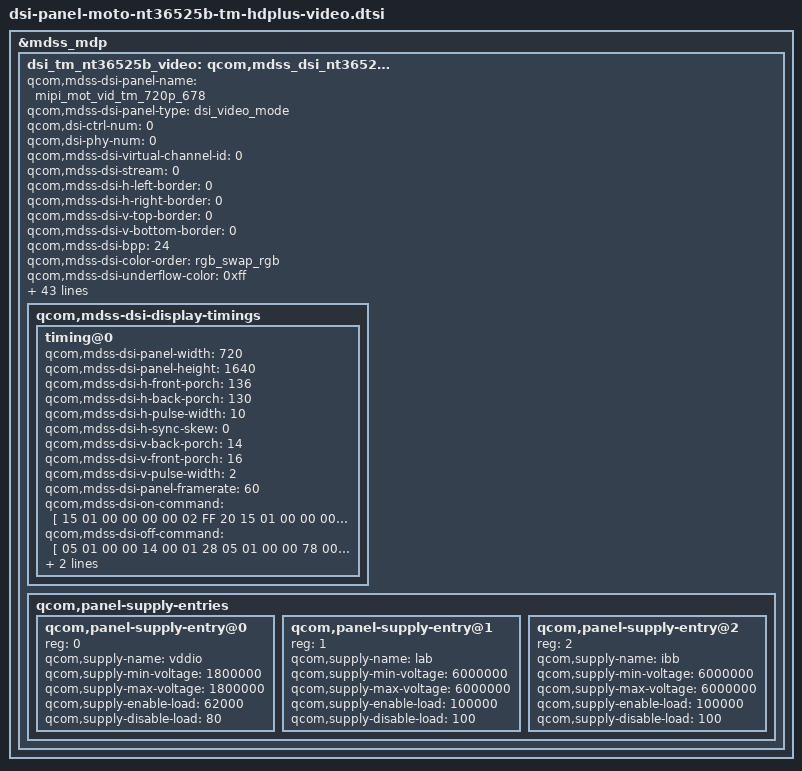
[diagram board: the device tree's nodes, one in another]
/* Copyright (c) 2015, 2018, The Linux Foundation. All rights reserved.
 *
 * This program is free software; you can redistribute it and/or modify
 * it under the terms of the GNU General Public License version 2 and
 * only version 2 as published by the Free Software Foundation.
 *
 * This program is distributed in the hope that it will be useful,
 * but WITHOUT ANY WARRANTY; without even the implied warranty of
 * MERCHANTABILITY or FITNESS FOR A PARTICULAR PURPOSE.  See the
 * GNU General Public License for more details.
 */

/*---------------------------------------------------------------------------
 * This file is autogenerated file using gcdb parser. Please do not edit it.
 * Update input XML file to add a new entry or update variable in this file
 * VERSION = "1.0"
 *---------------------------------------------------------------------------
 */

&mdss_mdp {
	dsi_tm_nt36525b_video:qcom,mdss_dsi_nt36525b_tm_video {
		qcom,mdss-dsi-panel-name ="mipi_mot_vid_tm_720p_678";
		qcom,mdss-dsi-panel-type = "dsi_video_mode";

		qcom,dsi-ctrl-num = <0>;
		qcom,dsi-phy-num = <0>;

		qcom,mdss-dsi-virtual-channel-id = <0>;
		qcom,mdss-dsi-stream = <0>;
		qcom,mdss-dsi-h-left-border = <0>;
		qcom,mdss-dsi-h-right-border = <0>;
		qcom,mdss-dsi-v-top-border = <0>;
		qcom,mdss-dsi-v-bottom-border = <0>;
		qcom,mdss-dsi-bpp = <24>;
		qcom,mdss-dsi-color-order = "rgb_swap_rgb";
		qcom,mdss-dsi-underflow-color = <0xff>;
		qcom,mdss-dsi-border-color = <0>;
		qcom,mdss-dsi-h-sync-pulse = <0>;
		qcom,mdss-dsi-traffic-mode = "non_burst_sync_event";
		qcom,mdss-dsi-lane-map = "lane_map_0123";
		qcom,mdss-dsi-bllp-eof-power-mode;
		qcom,mdss-dsi-bllp-power-mode;
		qcom,mdss-dsi-tx-eot-append;
		qcom,mdss-dsi-lane-0-state;
		qcom,mdss-dsi-lane-1-state;
		qcom,mdss-dsi-lane-2-state;
		qcom,mdss-dsi-lane-3-state;
		qcom,mdss-dsi-dma-trigger = "trigger_sw";
		qcom,mdss-dsi-mdp-trigger = "none";
		qcom,mdss-dsi-lp11-init;
		//qcom,mdss-dsi-reset-always-high;
		//qcom,mdss-panel-on-tp-rst-enable;
		qcom,mdss-dsi-reset-sequence = <1 10>, <0 10>, <1 10>;
		qcom,mdss-pan-physical-width-dimension = <69>;
		qcom,mdss-pan-physical-height-dimension = <158>;

		qcom,mdss-dsi-bl-pmic-control-type = "bl_ctrl_wled";
		qcom,mdss-dsi-bl-min-level = <1>;
		qcom,mdss-dsi-bl-max-level = <2047>;
		qcom,mdss-dsi-bl-default-level = <127>;

		qcom,mdss-dsi-cabc-ui-command = [15 01 00 00 00 00 02 55 00];
		qcom,mdss-dsi-cabc-ui-command-state = "dsi_hs_mode";
		qcom,mdss-dsi-cabc-mv-command = [15 01 00 00 00 00 02 55 00];
		qcom,mdss-dsi-cabc-mv-command-state = "dsi_hs_mode";
		qcom,mdss-dsi-cabc-dis-command = [15 01 00 00 00 00 02 55 00];
		qcom,mdss-dsi-cabc-dis-command-state = "dsi_hs_mode";
		qcom,mdss-dsi-hbm-on-command = [39 01 00 00 00 00 03 51 07 FF];
		qcom,mdss-dsi-hbm-on-command-state = "dsi_hs_mode";
		qcom,mdss-dsi-hbm-off-command = [39 01 00 00 00 00 03 51 06 66];
		qcom,mdss-dsi-hbm-off-command-state = "dsi_hs_mode";

		qcom,mdss-dsi-display-timings {
			timing@0{
				qcom,mdss-dsi-panel-width = <720>;
				qcom,mdss-dsi-panel-height = <1640>;
				qcom,mdss-dsi-h-front-porch = <136>;
				qcom,mdss-dsi-h-back-porch = <130>;
				qcom,mdss-dsi-h-pulse-width = <10>;
				qcom,mdss-dsi-h-sync-skew = <0>;
				qcom,mdss-dsi-v-back-porch = <14>;
				qcom,mdss-dsi-v-front-porch = <16>;
				qcom,mdss-dsi-v-pulse-width = <2>;
				qcom,mdss-dsi-panel-framerate = <60>;
				qcom,mdss-dsi-on-command = [
					15 01 00 00 00 00 02 FF 20
					15 01 00 00 00 00 02 FB 01
					15 01 00 00 00 00 02 05 A9
					15 01 00 00 00 00 02 07 6E
					15 01 00 00 00 00 02 08 AD
					15 01 00 00 00 00 02 0E 87
					15 01 00 00 00 00 02 0F 46
					15 01 00 00 00 00 02 69 A9
					15 01 00 00 00 00 02 87 02
					15 01 00 00 00 00 02 89 C1
					15 01 00 00 00 00 02 8A A8
					15 01 00 00 00 00 02 8B B1
					15 01 00 00 00 00 02 8C A8
					15 01 00 00 00 00 02 94 40
					15 01 00 00 00 00 02 95 D7
					15 01 00 00 00 00 02 96 13
					15 01 00 00 00 00 02 23 01
					15 01 00 00 00 00 02 24 01
					15 01 00 00 00 00 02 25 25
					15 01 00 00 00 00 02 26 92
					15 01 00 00 00 00 02 FF 24
					15 01 00 00 00 00 02 FB 01
					15 01 00 00 00 00 02 00 00
					15 01 00 00 00 00 02 01 1E
					15 01 00 00 00 00 02 02 23
					15 01 00 00 00 00 02 03 08
					15 01 00 00 00 00 02 04 08
					15 01 00 00 00 00 02 05 20
					15 01 00 00 00 00 02 06 20
					15 01 00 00 00 00 02 07 04
					15 01 00 00 00 00 02 08 05
					15 01 00 00 00 00 02 09 0F
					15 01 00 00 00 00 02 0A 0E
					15 01 00 00 00 00 02 0B 0D
					15 01 00 00 00 00 02 0C 0C
					15 01 00 00 00 00 02 16 20
					15 01 00 00 00 00 02 17 1E
					15 01 00 00 00 00 02 18 23
					15 01 00 00 00 00 02 19 08
					15 01 00 00 00 00 02 1A 08
					15 01 00 00 00 00 02 1B 20
					15 01 00 00 00 00 02 1C 20
					15 01 00 00 00 00 02 1D 04
					15 01 00 00 00 00 02 1E 05
					15 01 00 00 00 00 02 1F 0F
					15 01 00 00 00 00 02 20 0E
					15 01 00 00 00 00 02 21 0D
					15 01 00 00 00 00 02 22 0C
					15 01 00 00 00 00 02 37 44
					15 01 00 00 00 00 02 2F 06
					15 01 00 00 00 00 02 30 04
					15 01 00 00 00 00 02 33 04
					15 01 00 00 00 00 02 34 06
					15 01 00 00 00 00 02 39 00
					15 01 00 00 00 00 02 3A 05
					15 01 00 00 00 00 02 3B A0
					15 01 00 00 00 00 02 3D 52
					15 01 00 00 00 00 02 3F 0A
					15 01 00 00 00 00 02 43 0A
					15 01 00 00 00 00 02 47 44
					15 01 00 00 00 00 02 4A 05
					15 01 00 00 00 00 02 4B A0
					15 01 00 00 00 00 02 4C 51
					15 01 00 00 00 00 02 4D 12
					15 01 00 00 00 00 02 4E 34
					15 01 00 00 00 00 02 51 43
					15 01 00 00 00 00 02 52 21
					15 01 00 00 00 00 02 55 44
					15 01 00 00 00 00 02 56 54
					15 01 00 00 00 00 02 58 21
					15 01 00 00 00 00 02 59 00
					15 01 00 00 00 00 02 5A 84
					15 01 00 00 00 00 02 5B 70
					15 01 00 00 00 00 02 5C 80
					15 01 00 00 00 00 02 5D 05
					15 01 00 00 00 00 02 5E 04
					15 01 00 00 00 00 02 60 80
					15 01 00 00 00 00 02 61 9A
					15 01 00 00 00 00 02 64 10
					15 01 00 00 00 00 02 85 02
					15 01 00 00 00 00 02 92 A1
					15 01 00 00 00 00 02 93 10
					15 01 00 00 00 00 02 94 10
					15 01 00 00 00 00 02 9D 30
					15 01 00 00 00 00 02 AB 00
					15 01 00 00 00 00 02 AC 00
					15 01 00 00 00 00 02 AD 00
					15 01 00 00 00 00 02 B0 05
					15 01 00 00 00 00 02 B1 9D
					15 01 00 00 00 00 02 FF 25
					15 01 00 00 00 00 02 FB 01
					15 01 00 00 00 00 02 0A 82
					15 01 00 00 00 00 02 0B 65
					15 01 00 00 00 00 02 0C 01
					15 01 00 00 00 00 02 17 82
					15 01 00 00 00 00 02 18 06
					15 01 00 00 00 00 02 19 0F
					15 01 00 00 00 00 02 1E 00
					15 01 00 00 00 00 02 1F 80
					15 01 00 00 00 00 02 20 7C
					15 01 00 00 00 00 02 23 05
					15 01 00 00 00 00 02 24 9D
					15 01 00 00 00 00 02 25 00
					15 01 00 00 00 00 02 26 80
					15 01 00 00 00 00 02 27 7C
					15 01 00 00 00 00 02 2A 05
					15 01 00 00 00 00 02 2B 9D
					15 01 00 00 00 00 02 2F 66
					15 01 00 00 00 00 02 30 00
					15 01 00 00 00 00 02 31 00
					15 01 00 00 00 00 02 32 00
					15 01 00 00 00 00 02 33 80
					15 01 00 00 00 00 02 34 7C
					15 01 00 00 00 00 02 37 05
					15 01 00 00 00 00 02 38 9D
					15 01 00 00 00 00 02 40 11
					15 01 00 00 00 00 02 41 80
					15 01 00 00 00 00 02 42 80
					15 01 00 00 00 00 02 43 7C
					15 01 00 00 00 00 02 46 05
					15 01 00 00 00 00 02 47 9D
					15 01 00 00 00 00 02 4A 00
					15 01 00 00 00 00 02 4B 05
					15 01 00 00 00 00 02 4C A0
					15 01 00 00 00 00 02 4F 80
					15 01 00 00 00 00 02 50 7C
					15 01 00 00 00 00 02 53 05
					15 01 00 00 00 00 02 54 9D
					15 01 00 00 00 00 02 55 05
					15 01 00 00 00 00 02 56 9D
					15 01 00 00 00 00 02 58 00
					15 01 00 00 00 00 02 59 00
					15 01 00 00 00 00 02 5A 22
					15 01 00 00 00 00 02 5B C0
					15 01 00 00 00 00 02 5C 00
					15 01 00 00 00 00 02 5D 05
					15 01 00 00 00 00 02 5E A0
					15 01 00 00 00 00 02 61 80
					15 01 00 00 00 00 02 62 7C
					15 01 00 00 00 00 02 65 05
					15 01 00 00 00 00 02 66 9D
					15 01 00 00 00 00 02 6B 44
					15 01 00 00 00 00 02 6C 0D
					15 01 00 00 00 00 02 6D 0D
					15 01 00 00 00 00 02 6E 0F
					15 01 00 00 00 00 02 6F 0F
					15 01 00 00 00 00 02 78 00
					15 01 00 00 00 00 02 79 60
					15 01 00 00 00 00 02 7A 00
					15 01 00 00 00 00 02 7B 01
					15 01 00 00 00 00 02 8A 02
					15 01 00 00 00 00 02 CA 1C
					15 01 00 00 00 00 02 CC 1C
					15 01 00 00 00 00 02 CD 00
					15 01 00 00 00 00 02 CE 00
					15 01 00 00 00 00 02 CF 1C
					15 01 00 00 00 00 02 D0 00
					15 01 00 00 00 00 02 D1 00
					15 01 00 00 00 00 02 D3 11
					15 01 00 00 00 00 02 D4 CC
					15 01 00 00 00 00 02 D5 11
					15 01 00 00 00 00 02 FF 26
					15 01 00 00 00 00 02 FB 01
					15 01 00 00 00 00 02 00 A1
					15 01 00 00 00 00 02 04 4A
					15 01 00 00 00 00 02 0C 0B
					15 01 00 00 00 00 02 0D 01
					15 01 00 00 00 00 02 0E 02
					15 01 00 00 00 00 02 0F 06
					15 01 00 00 00 00 02 10 07
					15 01 00 00 00 00 02 11 00
					15 01 00 00 00 00 02 13 28
					15 01 00 00 00 00 02 14 94
					15 01 00 00 00 00 02 16 81
					15 01 00 00 00 00 02 19 1A
					15 01 00 00 00 00 02 1A 00
					15 01 00 00 00 00 02 1B 12
					15 01 00 00 00 00 02 1C 82
					15 01 00 00 00 00 02 1D 00
					15 01 00 00 00 00 02 1E A1
					15 01 00 00 00 00 02 1F A1
					15 01 00 00 00 00 02 24 01
					15 01 00 00 00 00 02 25 A1
					15 01 00 00 00 00 02 2F 03
					15 01 00 00 00 00 02 30 A2
					15 01 00 00 00 00 02 31 11
					15 01 00 00 00 00 02 32 11
					15 01 00 00 00 00 02 34 03
					15 01 00 00 00 00 02 35 A2
					15 01 00 00 00 00 02 36 78
					15 01 00 00 00 00 02 37 16
					15 01 00 00 00 00 02 38 11
					15 01 00 00 00 00 02 3F 04
					15 01 00 00 00 00 02 40 A1
					15 01 00 00 00 00 02 41 00
					15 01 00 00 00 00 02 42 00
					15 01 00 00 00 00 02 49 00
					15 01 00 00 00 00 02 58 C5
					15 01 00 00 00 00 02 59 C5
					15 01 00 00 00 00 02 5A C5
					15 01 00 00 00 00 02 5B BE
					15 01 00 00 00 00 02 5C 01
					15 01 00 00 00 00 02 5D 06
					15 01 00 00 00 00 02 5E 04
					15 01 00 00 00 00 02 5F 00
					15 01 00 00 00 00 02 60 00
					15 01 00 00 00 00 02 61 00
					15 01 00 00 00 00 02 62 00
					15 01 00 00 00 00 02 63 60
					15 01 00 00 00 00 02 64 B0
					15 01 00 00 00 00 02 65 05
					15 01 00 00 00 00 02 66 50
					15 01 00 00 00 00 02 67 94
					15 01 00 00 00 00 02 68 7C
					15 01 00 00 00 00 02 6B 00
					15 01 00 00 00 00 02 6C 00
					15 01 00 00 00 00 02 6D 00
					15 01 00 00 00 00 02 70 05
					15 01 00 00 00 00 02 71 9D
					15 01 00 00 00 00 02 73 80
					15 01 00 00 00 00 02 74 7C
					15 01 00 00 00 00 02 77 05
					15 01 00 00 00 00 02 78 9D
					15 01 00 00 00 00 02 7A 80
					15 01 00 00 00 00 02 7B 7C
					15 01 00 00 00 00 02 7E 05
					15 01 00 00 00 00 02 7F 9D
					15 01 00 00 00 00 02 82 60
					15 01 00 00 00 00 02 83 B0
					15 01 00 00 00 00 02 84 05
					15 01 00 00 00 00 02 85 50
					15 01 00 00 00 00 02 86 80
					15 01 00 00 00 00 02 87 7C
					15 01 00 00 00 00 02 8A 05
					15 01 00 00 00 00 02 8B 9D
					15 01 00 00 00 00 02 8C 00
					15 01 00 00 00 00 02 8D 00
					15 01 00 00 00 00 02 8E 01
					15 01 00 00 00 00 02 8F 00
					15 01 00 00 00 00 02 90 00
					15 01 00 00 00 00 02 91 00
					15 01 00 00 00 00 02 92 06
					15 01 00 00 00 00 02 93 68
					15 01 00 00 00 00 02 94 00
					15 01 00 00 00 00 02 96 00
					15 01 00 00 00 00 02 99 0D
					15 01 00 00 00 00 02 9A 36
					15 01 00 00 00 00 02 9B 0C
					15 01 00 00 00 00 02 9C 9E
					15 01 00 00 00 00 02 44 0E
					15 01 00 00 00 00 02 45 0E
					15 01 00 00 00 00 02 A9 4E
					15 01 00 00 00 00 02 AA 30
					15 01 00 00 00 00 02 AB 40
					15 01 00 00 00 00 02 AC 2A
					15 01 00 00 00 00 02 AD 4A
					15 01 00 00 00 00 02 AE 42
					15 01 00 00 00 00 02 AF 2E
					15 01 00 00 00 00 02 B0 32
					15 01 00 00 00 00 02 B1 4C
					15 01 00 00 00 00 02 B2 36
					15 01 00 00 00 00 02 B3 44
					15 01 00 00 00 00 02 B4 3A
					15 01 00 00 00 00 02 B5 48
					15 01 00 00 00 00 02 B6 3E
					15 01 00 00 00 00 02 FF 27
					15 01 00 00 00 00 02 FB 01
					15 01 00 00 00 00 02 13 00
					15 01 00 00 00 00 02 96 03
					15 01 00 00 00 00 02 97 13
					15 01 00 00 00 00 02 98 88
					15 01 00 00 00 00 02 99 01
					15 01 00 00 00 00 02 9D 15
					15 01 00 00 00 00 02 9E 55
					15 01 00 00 00 00 02 9F 04
					15 01 00 00 00 00 02 A9 14
					15 01 00 00 00 00 02 AA 00
					15 01 00 00 00 00 02 AB 14
					15 01 00 00 00 00 02 AC 00
					15 01 00 00 00 00 02 AD 15
					15 01 00 00 00 00 02 AE 55
					15 01 00 00 00 00 02 AF 04
					15 01 00 00 00 00 02 B0 03
					15 01 00 00 00 00 02 B3 C7
					15 01 00 00 00 00 02 FF 20
					15 01 00 00 00 00 02 FB 01
					39 01 00 00 00 00 11 B0 00 08 00 1D 00 3C 00 56 00 6C 00 80 00 92 00 A3
					39 01 00 00 00 00 11 B1 00 B2 00 E6 01 0C 01 4A 01 75 01 BD 01 F2 01 F4
					39 01 00 00 00 00 11 B2 02 28 02 65 02 8F 02 C4 02 EF 03 1E 03 2F 03 3F
					39 01 00 00 00 00 0D B3 03 51 03 67 03 83 03 AC 03 D3 03 D8
					39 01 00 00 00 00 11 B4 00 08 00 1D 00 3C 00 56 00 6C 00 80 00 92 00 A3
					39 01 00 00 00 00 11 B5 00 B2 00 E6 01 0C 01 4A 01 75 01 BD 01 F2 01 F4
					39 01 00 00 00 00 11 B6 02 28 02 65 02 8F 02 C4 02 EF 03 1E 03 2F 03 3F
					39 01 00 00 00 00 0D B7 03 51 03 67 03 83 03 AC 03 D3 03 D8
					39 01 00 00 00 00 11 B8 00 08 00 1D 00 3C 00 56 00 6C 00 80 00 92 00 A3
					39 01 00 00 00 00 11 B9 00 B2 00 E6 01 0C 01 4A 01 75 01 BD 01 F2 01 F4
					39 01 00 00 00 00 11 BA 02 28 02 65 02 8F 02 C4 02 EF 03 1E 03 2F 03 3F
					39 01 00 00 00 00 0D BB 03 51 03 67 03 83 03 AC 03 D3 03 D8
					15 01 00 00 00 00 02 C6 40
					15 01 00 00 00 00 02 C7 00
					15 01 00 00 00 00 02 C8 60
					15 01 00 00 00 00 02 C9 20
					15 01 00 00 00 00 02 CA 20
					15 01 00 00 00 00 02 CB 40
					15 01 00 00 00 00 02 CC 00
					15 01 00 00 00 00 02 CD 60
					15 01 00 00 00 00 02 CE 20
					15 01 00 00 00 00 02 CF 20
					15 01 00 00 00 00 02 D0 40
					15 01 00 00 00 00 02 D1 00
					15 01 00 00 00 00 02 D2 60
					15 01 00 00 00 00 02 D3 20
					15 01 00 00 00 00 02 D4 20
					15 01 00 00 00 00 02 D5 40
					15 01 00 00 00 00 02 D6 00
					15 01 00 00 00 00 02 D7 60
					15 01 00 00 00 00 02 D8 20
					15 01 00 00 00 00 02 D9 20
					15 01 00 00 00 00 02 DA 40
					15 01 00 00 00 00 02 DB 00
					15 01 00 00 00 00 02 DC 60
					15 01 00 00 00 00 02 DD 20
					15 01 00 00 00 00 02 DE 20
					15 01 00 00 00 00 02 DF 40
					15 01 00 00 00 00 02 E0 00
					15 01 00 00 00 00 02 E1 60
					15 01 00 00 00 00 02 E2 20
					15 01 00 00 00 00 02 E3 20
					15 01 00 00 00 00 02 FF 21
					15 01 00 00 00 00 02 FB 01
					39 01 00 00 00 00 11 B0 00 00 00 15 00 34 00 4E 00 64 00 78 00 8A 00 9B
					39 01 00 00 00 00 11 B1 00 AA 00 DE 01 04 01 42 01 6D 01 B5 01 EA 01 EC
					39 01 00 00 00 00 11 B2 02 20 02 5D 02 87 02 BC 02 E7 03 16 03 27 03 37
					39 01 00 00 00 00 0D B3 03 49 03 5F 03 7B 03 A4 03 CB 03 D0
					39 01 00 00 00 00 11 B4 00 00 00 15 00 34 00 4E 00 64 00 78 00 8A 00 9B
					39 01 00 00 00 00 11 B5 00 AA 00 DE 01 04 01 42 01 6D 01 B5 01 EA 01 EC
					39 01 00 00 00 00 11 B6 02 20 02 5D 02 87 02 BC 02 E7 03 16 03 27 03 37
					39 01 00 00 00 00 0D B7 03 49 03 5F 03 7B 03 A4 03 CB 03 D0
					39 01 00 00 00 00 11 B8 00 00 00 15 00 34 00 4E 00 64 00 78 00 8A 00 9B
					39 01 00 00 00 00 11 B9 00 AA 00 DE 01 04 01 42 01 6D 01 B5 01 EA 01 EC
					39 01 00 00 00 00 11 BA 02 20 02 5D 02 87 02 BC 02 E7 03 16 03 27 03 37
					39 01 00 00 00 00 0D BB 03 49 03 5F 03 7B 03 A4 03 CB 03 D0
					15 01 00 00 00 00 02 FF E0
					15 01 00 00 00 00 02 FB 01
					15 01 00 00 00 00 02 1F C0
					15 01 00 00 00 00 02 FF 23
					15 01 00 00 00 00 02 FB 01
					15 01 00 00 00 00 02 00 80
					15 01 00 00 00 00 02 07 00
					15 01 00 00 00 00 02 08 01
					15 01 00 00 00 00 02 09 80
					15 01 00 00 00 00 02 10 40
					15 01 00 00 00 00 02 11 00
					15 01 00 00 00 00 02 12 B8
					15 01 00 00 00 00 02 15 E3
					15 01 00 00 00 00 02 16 0B
					15 01 00 00 00 00 02 19 00
					15 01 00 00 00 00 02 1A 04
					15 01 00 00 00 00 02 1B 08
					15 01 00 00 00 00 02 1C 0C
					15 01 00 00 00 00 02 1D 10
					15 01 00 00 00 00 02 1E 14
					15 01 00 00 00 00 02 1F 18
					15 01 00 00 00 00 02 20 1C
					15 01 00 00 00 00 02 21 20
					15 01 00 00 00 00 02 22 24
					15 01 00 00 00 00 02 23 28
					15 01 00 00 00 00 02 24 2C
					15 01 00 00 00 00 02 25 30
					15 01 00 00 00 00 02 26 34
					15 01 00 00 00 00 02 27 38
					15 01 00 00 00 00 02 28 3C
					15 01 00 00 00 00 02 29 90
					15 01 00 00 00 00 02 2A 20
					15 01 00 00 00 00 02 2B A0
					15 01 00 00 00 00 02 30 FF
					15 01 00 00 00 00 02 31 FF
					15 01 00 00 00 00 02 32 FE
					15 01 00 00 00 00 02 33 F8
					15 01 00 00 00 00 02 34 F6
					15 01 00 00 00 00 02 35 F2
					15 01 00 00 00 00 02 36 ED
					15 01 00 00 00 00 02 37 EC
					15 01 00 00 00 00 02 38 E9
					15 01 00 00 00 00 02 39 E6
					15 01 00 00 00 00 02 3A E2
					15 01 00 00 00 00 02 3B DE
					15 01 00 00 00 00 02 3D DA
					15 01 00 00 00 00 02 3F D6
					15 01 00 00 00 00 02 40 D2
					15 01 00 00 00 00 02 41 CE
					15 01 00 00 00 00 02 45 FF
					15 01 00 00 00 00 02 46 FD
					15 01 00 00 00 00 02 47 F9
					15 01 00 00 00 00 02 48 F2
					15 01 00 00 00 00 02 49 EB
					15 01 00 00 00 00 02 4A E2
					15 01 00 00 00 00 02 4B D8
					15 01 00 00 00 00 02 4C CE
					15 01 00 00 00 00 02 4D C3
					15 01 00 00 00 00 02 4E B9
					15 01 00 00 00 00 02 4F B0
					15 01 00 00 00 00 02 50 A8
					15 01 00 00 00 00 02 51 A1
					15 01 00 00 00 00 02 52 9A
					15 01 00 00 00 00 02 53 97
					15 01 00 00 00 00 02 54 95
					15 01 00 00 00 00 02 58 FF
					15 01 00 00 00 00 02 59 FB
					15 01 00 00 00 00 02 5A F7
					15 01 00 00 00 00 02 5B EE
					15 01 00 00 00 00 02 5C E6
					15 01 00 00 00 00 02 5D DC
					15 01 00 00 00 00 02 5E D6
					15 01 00 00 00 00 02 5F CE
					15 01 00 00 00 00 02 60 C3
					15 01 00 00 00 00 02 61 C0
					15 01 00 00 00 00 02 62 BC
					15 01 00 00 00 00 02 63 B8
					15 01 00 00 00 00 02 64 B4
					15 01 00 00 00 00 02 65 B0
					15 01 00 00 00 00 02 66 AC
					15 01 00 00 00 00 02 67 A8
					15 01 00 00 00 00 02 FF 10
					15 01 00 00 00 00 02 FB 01
					15 01 00 00 00 00 02 BA 03
					15 01 00 00 00 00 02 35 00
					39 01 00 00 00 00 03 51 FF FF
					15 01 00 00 00 00 02 53 24
					15 01 00 00 00 00 02 55 00
					05 01 00 00 64 00 01 11
					05 01 00 00 00 00 01 29
					];
				qcom,mdss-dsi-off-command = [
					05 01 00 00 14 00 01 28
					05 01 00 00 78 00 01 10
					];
				qcom,mdss-dsi-on-command-state = "dsi_lp_mode";
				qcom,mdss-dsi-off-command-state = "dsi_lp_mode";
			};
		};

		qcom,panel-supply-entries {
			#address-cells = <1>;
			#size-cells = <0>;

			qcom,panel-supply-entry@0 {
				reg = <0>;
				qcom,supply-name = "vddio";
				qcom,supply-min-voltage = <1800000>;
				qcom,supply-max-voltage = <1800000>;
				qcom,supply-enable-load = <62000>;
				qcom,supply-disable-load = <80>;
			};

			qcom,panel-supply-entry@1 {
				reg = <1>;
				qcom,supply-name = "lab";
				qcom,supply-min-voltage = <6000000>;
				qcom,supply-max-voltage = <6000000>;
				qcom,supply-enable-load = <100000>;
				qcom,supply-disable-load = <100>;
			};

			qcom,panel-supply-entry@2 {
				reg = <2>;
				qcom,supply-name = "ibb";
				qcom,supply-min-voltage = <6000000>;
				qcom,supply-max-voltage = <6000000>;
				qcom,supply-enable-load = <100000>;
				qcom,supply-disable-load = <100>;
			};
		};
	};
};

